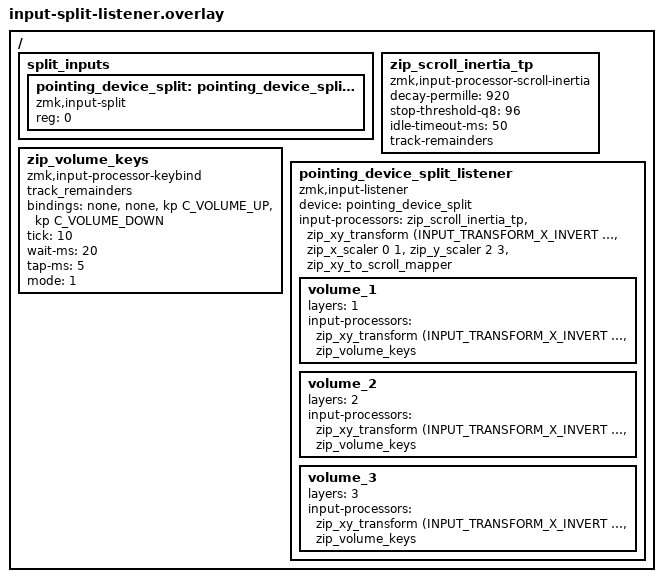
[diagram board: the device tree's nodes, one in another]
#include <dt-bindings/zmk/keys.h>

/{
    split_inputs {
        #address-cells = <1>;
        #size-cells = <0>;

        pointing_device_split: pointing_device_split@0 {
            compatible = "zmk,input-split";
            reg = <0>;
        };
    };

    zip_scroll_inertia_tp: zip_scroll_inertia_tp {
        compatible = "zmk,input-processor-scroll-inertia";
        #input-processor-cells = <0>;
        decay-permille = <920>;
        stop-threshold-q8 = <96>;
        idle-timeout-ms = <50>;
        track-remainders;
    };

    zip_volume_keys: zip_volume_keys {
        compatible = "zmk,input-processor-keybind";
        #input-processor-cells = <0>;
        track_remainders;
        bindings = <&none>, <&none>, <&kp C_VOLUME_UP>, <&kp C_VOLUME_DOWN>;
        tick = <10>;
        wait-ms = <20>;
        tap-ms = <5>;
        mode = <1>;
    };

    pointing_device_split_listener: pointing_device_split_listener {
        compatible = "zmk,input-listener";
        device = <&pointing_device_split>;
        status = "okay";
        input-processors = <&zip_scroll_inertia_tp &zip_xy_transform (INPUT_TRANSFORM_X_INVERT | INPUT_TRANSFORM_Y_INVERT) &zip_x_scaler 0 1 &zip_y_scaler 2 3 &zip_xy_to_scroll_mapper>;

        volume_1 {
            layers = <1>;
            input-processors = <&zip_xy_transform (INPUT_TRANSFORM_X_INVERT | INPUT_TRANSFORM_Y_INVERT) &zip_volume_keys>;
        };

        volume_2 {
            layers = <2>;
            input-processors = <&zip_xy_transform (INPUT_TRANSFORM_X_INVERT | INPUT_TRANSFORM_Y_INVERT) &zip_volume_keys>;
        };

        volume_3 {
            layers = <3>;
            input-processors = <&zip_xy_transform (INPUT_TRANSFORM_X_INVERT | INPUT_TRANSFORM_Y_INVERT) &zip_volume_keys>;
        };
     };
};
